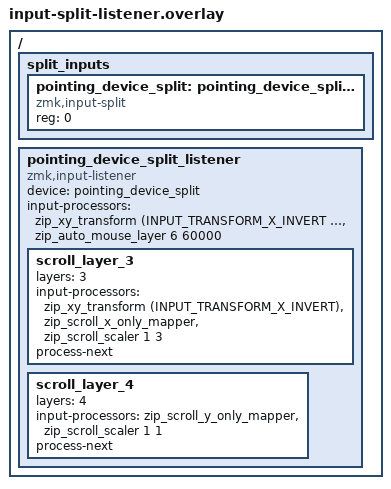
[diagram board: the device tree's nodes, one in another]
/{
    split_inputs {
        #address-cells = <1>;
        #size-cells = <0>;

        pointing_device_split: pointing_device_split@0 {
            compatible = "zmk,input-split";
            reg = <0>;
        };
    };

    pointing_device_split_listener: pointing_device_split_listener {
        compatible = "zmk,input-listener";
        device = <&pointing_device_split>;
        status = "okay";
        input-processors = <&zip_xy_transform (INPUT_TRANSFORM_X_INVERT | INPUT_TRANSFORM_Y_INVERT)>, <&zip_auto_mouse_layer 6 60000>;

        scroll_layer_3 {
            layers = <3>;
            input-processors = <&zip_xy_transform (INPUT_TRANSFORM_X_INVERT)>, <&zip_scroll_x_only_mapper>, <&zip_scroll_scaler 1 3>;
            process-next;
        };

        scroll_layer_4 {
            layers = <4>;
            input-processors = <&zip_scroll_y_only_mapper>, <&zip_scroll_scaler 1 1>;
            process-next;
        };
     };
};
